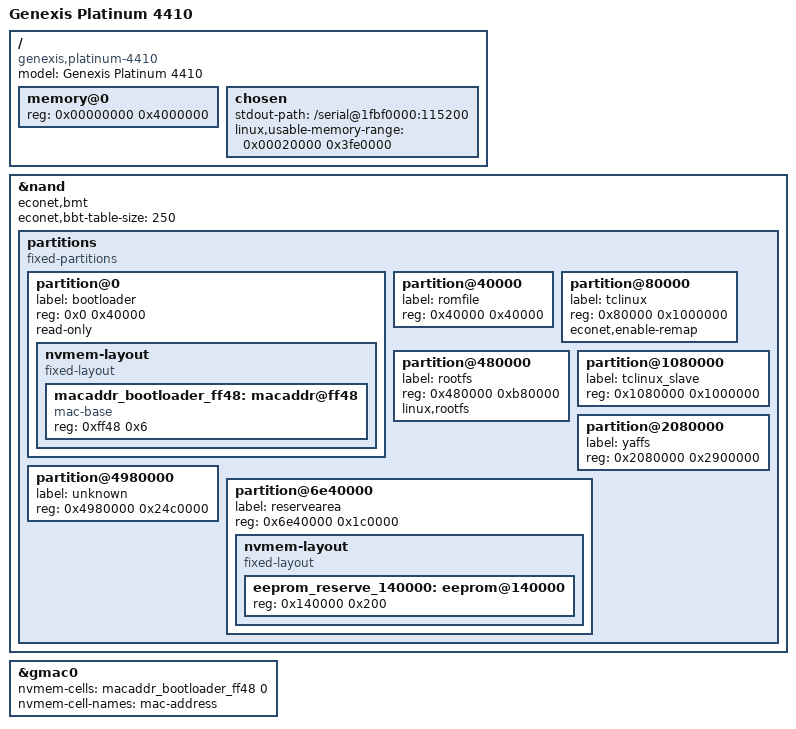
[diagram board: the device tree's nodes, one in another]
// SPDX-License-Identifier: (GPL-2.0-only OR BSD-2-Clause)
/dts-v1/;

#include "en751221.dtsi"

/ {
	model = "Genexis Platinum 4410";
	compatible = "genexis,platinum-4410", "econet,en751221";

	memory@0 {
		device_type = "memory";
		reg = <0x00000000 0x4000000>;
	};

	chosen {
		stdout-path = "/serial@1fbf0000:115200";
		linux,usable-memory-range = <0x00020000 0x3fe0000>;
	};
};

&nand {
	status = "okay";
	econet,bmt;
	econet,bbt-table-size = <250>;

	partitions {
		compatible = "fixed-partitions";
		#address-cells = <1>;
		#size-cells = <1>;

		partition@0 {
			label = "bootloader";
			reg = <0x0 0x40000>;
			read-only;

			nvmem-layout {
				compatible = "fixed-layout";
				#address-cells = <1>;
				#size-cells = <1>;

				macaddr_bootloader_ff48: macaddr@ff48 {
					compatible = "mac-base";
					reg = <0xff48 0x6>;
					#nvmem-cell-cells = <1>;
				};
			};
		};

		partition@40000 {
			label = "romfile";
			reg = <0x40000 0x40000>;
		};

		partition@80000 {
			label = "tclinux";
			reg = <0x80000 0x1000000>;
			econet,enable-remap;
		};

		/* Nested inside of tclinux */
		partition@480000 {
			label = "rootfs";
			reg = <0x480000 0xb80000>;
			linux,rootfs;
		};

		partition@1080000 {
			label = "tclinux_slave";
			reg = <0x1080000 0x1000000>;
		};

		partition@2080000 {
			label = "yaffs";
			reg = <0x2080000 0x2900000>;
		};

		partition@4980000 {
			label = "unknown";
			reg = <0x4980000 0x24c0000>;
		};

		partition@6e40000 {
			label = "reservearea";
			reg = <0x6e40000 0x1c0000>;

			nvmem-layout {
				compatible = "fixed-layout";
				#address-cells = <1>;
				#size-cells = <1>;

				eeprom_reserve_140000: eeprom@140000 {
					reg = <0x140000 0x200>;
				};
			};
		};
	};
};

&gmac0 {
	status = "okay";
	nvmem-cells = <&macaddr_bootloader_ff48 0>;
	nvmem-cell-names = "mac-address";
};
